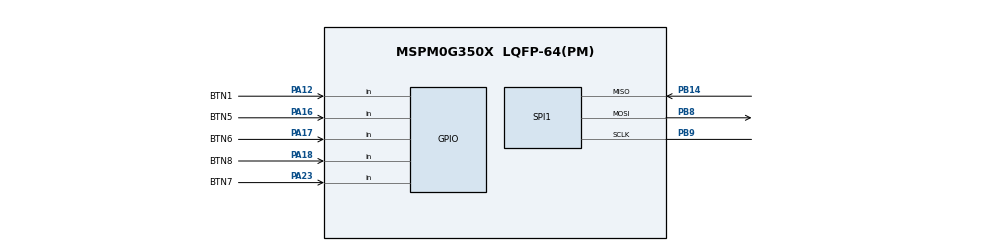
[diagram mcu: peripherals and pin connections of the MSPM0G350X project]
/**
 * @cliArgs --device "MSPM0G350X" --part "Default" --package "LQFP-64(PM)" --product "mspm0_sdk@2.10.00.04"
 * @versions {"tool":"1.26.2+4477"}
 */

/**
 * Import the modules used in this configuration.
 */
const GPIO   = scripting.addModule("/ti/driverlib/GPIO", {}, false);
const GPIO1  = GPIO.addInstance();
const GPIO2  = GPIO.addInstance();
const GPIO3  = GPIO.addInstance();
const RTC    = scripting.addModule("/ti/driverlib/RTC");
const SPI    = scripting.addModule("/ti/driverlib/SPI", {}, false);
const SPI1   = SPI.addInstance();
const SYSCTL = scripting.addModule("/ti/driverlib/SYSCTL");
const TIMER  = scripting.addModule("/ti/driverlib/TIMER", {}, false);
const TIMER1 = TIMER.addInstance();

/**
 * Write custom configuration values to the imported modules.
 */
GPIO1.$name                                 = "OLED_CTRL";
GPIO1.associatedPins.create(3);
GPIO1.associatedPins[0].$name               = "CS";
GPIO1.associatedPins[0].initialValue        = "SET";
GPIO1.associatedPins[0].ioStructure         = "SD";
GPIO1.associatedPins[0].assignedPin         = "3";
GPIO1.associatedPins[0].assignedPort        = "PORTB";
GPIO1.associatedPins[0].assignedPortSegment = "Lower";
GPIO1.associatedPins[1].$name               = "DC";
GPIO1.associatedPins[1].initialValue        = "SET";
GPIO1.associatedPins[1].ioStructure         = "SD";
GPIO1.associatedPins[1].assignedPort        = "PORTB";
GPIO1.associatedPins[1].assignedPortSegment = "Lower";
GPIO1.associatedPins[1].assignedPin         = "6";
GPIO1.associatedPins[2].$name               = "RST";
GPIO1.associatedPins[2].initialValue        = "SET";
GPIO1.associatedPins[2].ioStructure         = "SD";
GPIO1.associatedPins[2].assignedPort        = "PORTB";
GPIO1.associatedPins[2].assignedPortSegment = "Lower";
GPIO1.associatedPins[2].assignedPin         = "7";

const Board = scripting.addModule("/ti/driverlib/Board", {}, false);

GPIO2.$name                                 = "BUTTONS";
GPIO2.associatedPins.create(8);
GPIO2.associatedPins[0].$name               = "BTN1";
GPIO2.associatedPins[0].direction           = "INPUT";
GPIO2.associatedPins[0].assignedPort        = "PORTA";
GPIO2.associatedPins[0].assignedPortSegment = "Lower";
GPIO2.associatedPins[0].internalResistor    = "PULL_UP";
GPIO2.associatedPins[0].assignedPin         = "12";
GPIO2.associatedPins[0].pin.$assign         = "PA12";
GPIO2.associatedPins[1].$name               = "BTN2";
GPIO2.associatedPins[1].direction           = "INPUT";
GPIO2.associatedPins[1].internalResistor    = "PULL_UP";
GPIO2.associatedPins[1].assignedPort        = "PORTA";
GPIO2.associatedPins[1].assignedPortSegment = "Lower";
GPIO2.associatedPins[1].assignedPin         = "13";
GPIO2.associatedPins[2].$name               = "BTN3";
GPIO2.associatedPins[2].direction           = "INPUT";
GPIO2.associatedPins[2].internalResistor    = "PULL_UP";
GPIO2.associatedPins[2].assignedPort        = "PORTA";
GPIO2.associatedPins[2].assignedPortSegment = "Lower";
GPIO2.associatedPins[2].assignedPin         = "14";
GPIO2.associatedPins[3].$name               = "BTN4";
GPIO2.associatedPins[3].direction           = "INPUT";
GPIO2.associatedPins[3].internalResistor    = "PULL_UP";
GPIO2.associatedPins[3].assignedPort        = "PORTA";
GPIO2.associatedPins[3].assignedPortSegment = "Lower";
GPIO2.associatedPins[3].assignedPin         = "15";
GPIO2.associatedPins[4].direction           = "INPUT";
GPIO2.associatedPins[4].internalResistor    = "PULL_UP";
GPIO2.associatedPins[4].assignedPort        = "PORTA";
GPIO2.associatedPins[4].assignedPortSegment = "Upper";
GPIO2.associatedPins[4].$name               = "BTN5";
GPIO2.associatedPins[4].assignedPin         = "16";
GPIO2.associatedPins[4].pin.$assign         = "PA16";
GPIO2.associatedPins[5].$name               = "BTN6";
GPIO2.associatedPins[5].assignedPortSegment = "Upper";
GPIO2.associatedPins[5].assignedPort        = "PORTA";
GPIO2.associatedPins[5].direction           = "INPUT";
GPIO2.associatedPins[5].internalResistor    = "PULL_UP";
GPIO2.associatedPins[5].assignedPin         = "17";
GPIO2.associatedPins[5].pin.$assign         = "PA17";
GPIO2.associatedPins[6].$name               = "BTN7";
GPIO2.associatedPins[6].direction           = "INPUT";
GPIO2.associatedPins[6].internalResistor    = "PULL_UP";
GPIO2.associatedPins[6].assignedPort        = "PORTA";
GPIO2.associatedPins[6].assignedPortSegment = "Upper";
GPIO2.associatedPins[6].assignedPin         = "23";
GPIO2.associatedPins[6].pin.$assign         = "PA23";
GPIO2.associatedPins[7].direction           = "INPUT";
GPIO2.associatedPins[7].internalResistor    = "PULL_UP";
GPIO2.associatedPins[7].assignedPort        = "PORTA";
GPIO2.associatedPins[7].assignedPortSegment = "Upper";
GPIO2.associatedPins[7].$name               = "BTN8";
GPIO2.associatedPins[7].assignedPin         = "18";
GPIO2.associatedPins[7].pin.$assign         = "PA18";

GPIO3.$name                                 = "BUZZER";
GPIO3.associatedPins[0].$name               = "PIN";
GPIO3.associatedPins[0].assignedPort        = "PORTA";
GPIO3.associatedPins[0].assignedPortSegment = "Upper";
GPIO3.associatedPins[0].assignedPin         = "24";

RTC.enableClock = true;

SPI1.$name                      = "SPI_0";
SPI1.chipSelect                 = [];
SPI1.frameFormat                = "MOTO3";
SPI1.sclkPinConfig.$name        = "ti_driverlib_gpio_GPIOPinGeneric0";
SPI1.mosiPinConfig.$name        = "ti_driverlib_gpio_GPIOPinGeneric1";
SPI1.misoPinConfig.$name        = "ti_driverlib_gpio_GPIOPinGeneric2";
SPI1.peripheral.sclkPin.$assign = "PB9";
SPI1.peripheral.mosiPin.$assign = "PB8";
SPI1.peripheral.misoPin.$assign = "PB14";

SYSCTL.forceDefaultClkConfig = true;

TIMER1.$name       = "TIMER_0";
TIMER1.timerClkDiv = 8;
TIMER1.timerPeriod = "16 ms";
TIMER1.interrupts  = ["ZERO"];
TIMER1.timerMode   = "PERIODIC";

/**
 * Pinmux solution for unlocked pins/peripherals. This ensures that minor changes to the automatic solver in a future
 * version of the tool will not impact the pinmux you originally saw.  These lines can be completely deleted in order to
 * re-solve from scratch.
 */
GPIO1.associatedPins[0].pin.$suggestSolution = "PB3";
GPIO1.associatedPins[1].pin.$suggestSolution = "PB6";
GPIO1.associatedPins[2].pin.$suggestSolution = "PB7";
Board.peripheral.$suggestSolution            = "DEBUGSS";
Board.peripheral.swclkPin.$suggestSolution   = "PA20";
Board.peripheral.swdioPin.$suggestSolution   = "PA19";
GPIO2.associatedPins[1].pin.$suggestSolution = "PA13";
GPIO2.associatedPins[2].pin.$suggestSolution = "PA14";
GPIO2.associatedPins[3].pin.$suggestSolution = "PA15";
GPIO3.associatedPins[0].pin.$suggestSolution = "PA24";
RTC.peripheral.$suggestSolution              = "RTC";
SPI1.peripheral.$suggestSolution             = "SPI1";
SYSCTL.peripheral.$suggestSolution           = "SYSCTL";
TIMER1.peripheral.$suggestSolution           = "TIMA0";
